AUTOSAR XML (schema 4.0)
standard types defined: float32, float64, sint16, sint32, sint8, uint16, uint32, uint8, void, boolean
package /ImplDataTypes
  7 x impl type, all with category=TYPE_REFERENCE, type-emitter=RTE:
    Impl_IoSpeedSensorReadingType: implementation-data-type=uint8
    Impl_MultiStateBtnType: implementation-data-type=uint8
    Impl_SensorType: implementation-data-type=uint8
    Impl_SpeedCtrlModeType: implementation-data-type=uint8
    Impl_SpeedModeBtnType: implementation-data-type=uint8
    Impl_SpeedMotorType: implementation-data-type=sint8
    Impl_SpeedType: implementation-data-type=uint8
package /MappingSets
  data type mapping set MappingSet: mode-request-type-map{implementation-data-type=uint8, mode-group=SpeedCtrlMode}
package /PortInterfaces/ClientServer
  client server interface CsIf_IoGetSensorSpeed
    operation IoGet
      arg Speed: type=Impl_IoSpeedSensorReadingType, direction=OUT
  client server interface CsIf_SpeedMotor
    operation Limit
      arg Speed: type=Impl_SpeedMotorType, direction=IN
  client server interface CsIf_SpeedSensor
    operation GetSpeed
      arg Speed: type=Impl_SensorType, direction=OUT
package /PortInterfaces/ModeSwitch
  mode switch interface MsIf_SpeedCtrlMode
    mode group SpeedCtrlMode: type=SpeedCtrlMode
  mode declaration group SpeedCtrlMode: category=ALPHABETIC_ORDER, initial-mode=INIT, on-transition-value=255
    mode INIT
    mode Mode_Auto
    mode Mode_Manual
package /PortInterfaces/SenderReceiver
  sender receiver interface SrIf_SpeedCtrlBtns
    data SpeedBtnState: type=Impl_MultiStateBtnType
  sender receiver interface SrIf_SpeedCtrlData
    data Speed: type=Impl_SpeedType
  sender receiver interface SrIf_SpeedModeBtn
    data SpeedModeBtn: type=Impl_SpeedModeBtnType
package /SoftwareComponents
  6 x swc implementation, all with programming-language=C, sw-version=1.0.0, vendor-id=255:
    Impl_SWC_Driver: behavior=Ibhv_SWC_Driver
      code-descriptors:
        code Code: artifact-descriptors=autosar-engineering-object={short-label=SWC.c, category=SWSRC}
      resource consumption ResourceConsumption
    Impl_SWC_ECU: behavior=Ibhv_SWC_ECU
      code-descriptors:
        code Code: artifact-descriptors=autosar-engineering-object={short-label=SWC.c, category=SWSRC}
      resource consumption ResourceConsumption
    Impl_SWC_IoHwAbs: behavior=Ibhv_SWC_IoHwAbs
      code-descriptors:
        code Code: artifact-descriptors=autosar-engineering-object={short-label=SWC.c, category=SWSRC}
      resource consumption ResourceConsumption
    Impl_SWC_SpeedMg: behavior=Ibhv_SWC_SpeedMg
      code-descriptors:
        code Code: artifact-descriptors=autosar-engineering-object={short-label=SWC.c, category=SWSRC}
      resource consumption ResourceConsumption
    Impl_SWC_SpeedSensor: behavior=Ibhv_SWC_SpeedSensor
      code-descriptors:
        code Code: artifact-descriptors=autosar-engineering-object={short-label=SWC.c, category=SWSRC}
      resource consumption ResourceConsumption
    Impl_SWC_VehicleMotor: behavior=Ibhv_SWC_VehicleMotor
      code-descriptors:
        code Code: artifact-descriptors=autosar-engineering-object={short-label=SWC.c, category=SWSRC}
      resource consumption ResourceConsumption
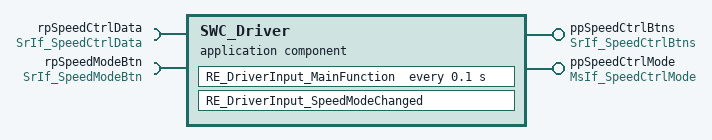
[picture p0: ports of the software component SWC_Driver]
  application sw component type SWC_Driver
    provide port ppSpeedCtrlBtns: provided-interface=SrIf_SpeedCtrlBtns
    provide port ppSpeedCtrlMode: provided-interface=MsIf_SpeedCtrlMode
    require port rpSpeedCtrlData: required-interface=SrIf_SpeedCtrlData
    require port rpSpeedModeBtn: required-interface=SrIf_SpeedModeBtn
    behavior Ibhv_SWC_Driver: data-type-mapping=MappingSet, handle-termination-and-restart=NO-SUPPORT
      data received event DRE_rpSpeedModeBtn_SpeedModeBtn: start-on-event=RE_DriverInput_SpeedModeChanged, data=rpSpeedModeBtn.SpeedModeBtn
      timing event TE_RE_DriverInput_MainFunction_100ms: start-on-event=RE_DriverInput_MainFunction, period=0.1
      runnable RE_DriverInput_MainFunction
        data-receive-point-by-arguments:
          access DRP_rpSpeedCtrlData_Speed: accessed-variable=rpSpeedCtrlData.Speed
        data-send-points:
          access DSP_ppSpeedCtrlBtns_SpeedBtnState: accessed-variable=ppSpeedCtrlBtns.SpeedBtnState
      runnable RE_DriverInput_SpeedModeChanged
        data-receive-point-by-arguments:
          access DRP_rpSpeedModeBtn_SpeedModeBtn: accessed-variable=rpSpeedModeBtn.SpeedModeBtn
        mode switch point MSP_ppSpeedCtrlMode_ppSpeedCtrlMode: mode-group=ppSpeedCtrlMode.SpeedCtrlMode
  application sw component type SWC_ECU
    provide port ppSpeedCtrlData: provided-interface=SrIf_SpeedCtrlData
    behavior Ibhv_SWC_ECU: data-type-mapping=MappingSet, handle-termination-and-restart=NO-SUPPORT
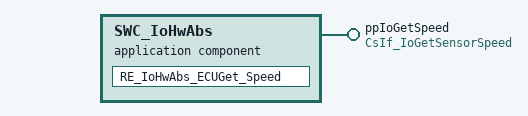
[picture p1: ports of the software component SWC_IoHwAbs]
  application sw component type SWC_IoHwAbs
    provide port ppIoGetSpeed: provided-interface=CsIf_IoGetSensorSpeed
    behavior Ibhv_SWC_IoHwAbs: data-type-mapping=MappingSet, handle-termination-and-restart=NO-SUPPORT
      operation invoked event OIE_ppIoGetSpeed_IoGet: start-on-event=RE_IoHwAbs_ECUGet_Speed, operation=ppIoGetSpeed.IoGet
      runnable RE_IoHwAbs_ECUGet_Speed
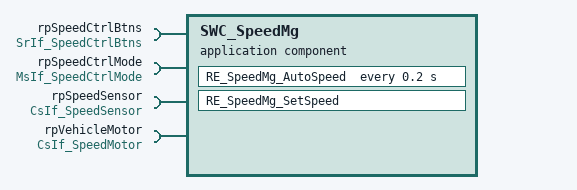
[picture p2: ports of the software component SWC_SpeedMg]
  application sw component type SWC_SpeedMg
    4 x require port:
      rpSpeedCtrlBtns: required-interface=SrIf_SpeedCtrlBtns
      rpSpeedCtrlMode: required-interface=MsIf_SpeedCtrlMode
      rpSpeedSensor: required-interface=CsIf_SpeedSensor
      rpVehicleMotor: required-interface=CsIf_SpeedMotor
    behavior Ibhv_SWC_SpeedMg: data-type-mapping=MappingSet, handle-termination-and-restart=NO-SUPPORT
      data received event DRE_rpSpeedCtrlBtns_DE_SpeedBtnState: start-on-event=RE_SpeedMg_SetSpeed, data=rpSpeedCtrlBtns.DE_SpeedBtnState
      swc mode switch event MSE_rpSpeedCtrlMode_Mode_Auto_ON_ENTRY: start-on-event=RE_SpeedMg_AutoSpeed, activation=ON-ENTRY, mode=rpSpeedCtrlMode.SpeedCtrlMode.Mode_Auto
      swc mode switch event MSE_rpSpeedCtrlMode_Mode_Manual_ON_ENTRY: start-on-event=RE_SpeedMg_SetSpeed, activation=ON-ENTRY, mode=rpSpeedCtrlMode.SpeedCtrlMode.Mode_Manual
      timing event TE_RE_SpeedMg_AutoSpeed_200ms: start-on-event=RE_SpeedMg_AutoSpeed, period=0.2
      runnable RE_SpeedMg_AutoSpeed
        data-receive-point-by-arguments:
          access DRP_rpSpeedCtrlBtns_DE_SpeedBtnState: accessed-variable=rpSpeedCtrlBtns.SpeedBtnState
        sync call SCP_rpSpeedSensor_GetSpeed: operation=rpSpeedSensor.GetSpeed, timeout=0.0
      runnable RE_SpeedMg_SetSpeed
        data-receive-point-by-arguments:
          access DRP_rpSpeedCtrlBtns_SpeedBtnState: accessed-variable=rpSpeedCtrlBtns.SpeedBtnState
        sync call SCP_rpVehicleMotor_Limit: operation=rpVehicleMotor.Limit, timeout=0.0
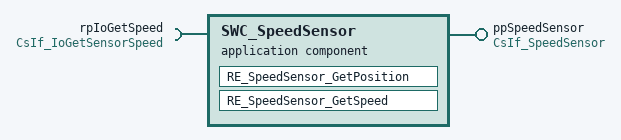
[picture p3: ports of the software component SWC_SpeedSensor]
  application sw component type SWC_SpeedSensor
    provide port ppSpeedSensor: provided-interface=CsIf_SpeedSensor
    require port rpIoGetSpeed: required-interface=CsIf_IoGetSensorSpeed
    behavior Ibhv_SWC_SpeedSensor: data-type-mapping=MappingSet, handle-termination-and-restart=NO-SUPPORT
      operation invoked event OIE_ppSpeedSensor_GetSpeed: start-on-event=RE_SpeedSensor_GetPosition, operation=ppSpeedSensor.GetSpeed
      runnable RE_SpeedSensor_GetPosition
      runnable RE_SpeedSensor_GetSpeed
        sync call SCP_rpIoGetSpeed_IoGet: operation=rpIoGetSpeed.IoGet, timeout=0.0
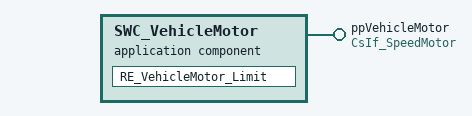
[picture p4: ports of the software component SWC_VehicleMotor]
  application sw component type SWC_VehicleMotor
    provide port ppVehicleMotor: provided-interface=CsIf_SpeedMotor
    behavior Ibhv_SWC_VehicleMotor: data-type-mapping=MappingSet, handle-termination-and-restart=NO-SUPPORT
      operation invoked event OIE_ppVehicleMotor_Limit: start-on-event=RE_VehicleMotor_Limit, operation=ppVehicleMotor.Limit
      runnable RE_VehicleMotor_Limit
package /Compositions
  composition sw component type SpeedLimiterComposition
    4 x component:
      SWC_Driver: type=SWC_Driver
      SWC_ECU: type=SWC_ECU
      SWC_SpeedMg: type=SWC_SpeedMg
      SWC_VehicleMotor: type=SWC_VehicleMotor
    connect SWC_Driver.ppSpeedCtrlBtns -> SWC_SpeedMg.rpSpeedCtrlBtns
    connect SWC_ECU.ppSpeedCtrlData -> SWC_Driver.rpSpeedCtrlData
    connect SWC_VehicleMotor.ppVehicleMotor -> SWC_SpeedMg.rpVehicleMotor
